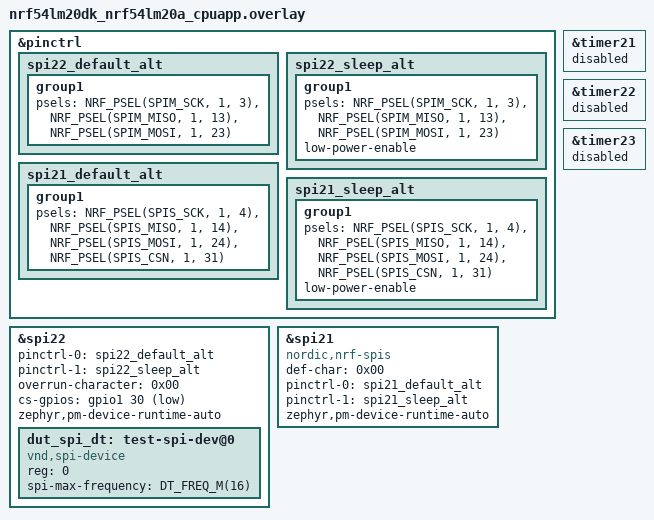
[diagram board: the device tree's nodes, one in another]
/*
 * Copyright (c) 2026 Nordic Semiconductor ASA
 *
 * SPDX-License-Identifier: LicenseRef-Nordic-5-Clause
 */
/* Test requires loopbacks:
 * - between P1.3 and P1.4.
 * - between P1.13 and P1.14.
 * - between P1.23 and P1.24,
 * - between P1.30 and P1.31,
 */

&pinctrl {
	spi22_default_alt: spi22_default_alt {
		group1 {
			psels = <NRF_PSEL(SPIM_SCK, 1, 3)>,
				<NRF_PSEL(SPIM_MISO, 1, 13)>,
				<NRF_PSEL(SPIM_MOSI, 1, 23)>;
		};
	};

	spi22_sleep_alt: spi22_sleep_alt {
		group1 {
			psels = <NRF_PSEL(SPIM_SCK, 1, 3)>,
				<NRF_PSEL(SPIM_MISO, 1, 13)>,
				<NRF_PSEL(SPIM_MOSI, 1, 23)>;
			low-power-enable;
		};
	};

	spi21_default_alt: spi21_default_alt {
		group1 {
			psels = <NRF_PSEL(SPIS_SCK, 1, 4)>,
				<NRF_PSEL(SPIS_MISO, 1, 14)>,
				<NRF_PSEL(SPIS_MOSI, 1, 24)>,
				<NRF_PSEL(SPIS_CSN, 1, 31)>;
		};
	};

	spi21_sleep_alt: spi21_sleep_alt {
		group1 {
			psels = <NRF_PSEL(SPIS_SCK, 1, 4)>,
				<NRF_PSEL(SPIS_MISO, 1, 14)>,
				<NRF_PSEL(SPIS_MOSI, 1, 24)>,
				<NRF_PSEL(SPIS_CSN, 1, 31)>;
			low-power-enable;
		};
	};
};

dut_cnt_timer: &timer21 {
	status = "reserved";
};

dut_trig_timer: &timer22 {
	status = "reserved";
};

test_timer: &timer23 {
	status = "reserved";
};

dut_spi: &spi22 {
	status = "okay";
	pinctrl-0 = <&spi22_default_alt>;
	pinctrl-1 = <&spi22_sleep_alt>;
	pinctrl-names = "default", "sleep";
	overrun-character = <0x00>;
	cs-gpios = <&gpio1 30 GPIO_ACTIVE_LOW>;
	zephyr,pm-device-runtime-auto;

	dut_spi_dt: test-spi-dev@0 {
		compatible = "vnd,spi-device";
		reg = <0>;
		spi-max-frequency = <DT_FREQ_M(16)>;
	};
};

dut_spis: &spi21 {
	compatible = "nordic,nrf-spis";
	status = "okay";
	def-char = <0x00>;
	pinctrl-0 = <&spi21_default_alt>;
	pinctrl-1 = <&spi21_sleep_alt>;
	pinctrl-names = "default", "sleep";
	/delete-property/ rx-delay-supported;
	/delete-property/ rx-delay;
	zephyr,pm-device-runtime-auto;
};
